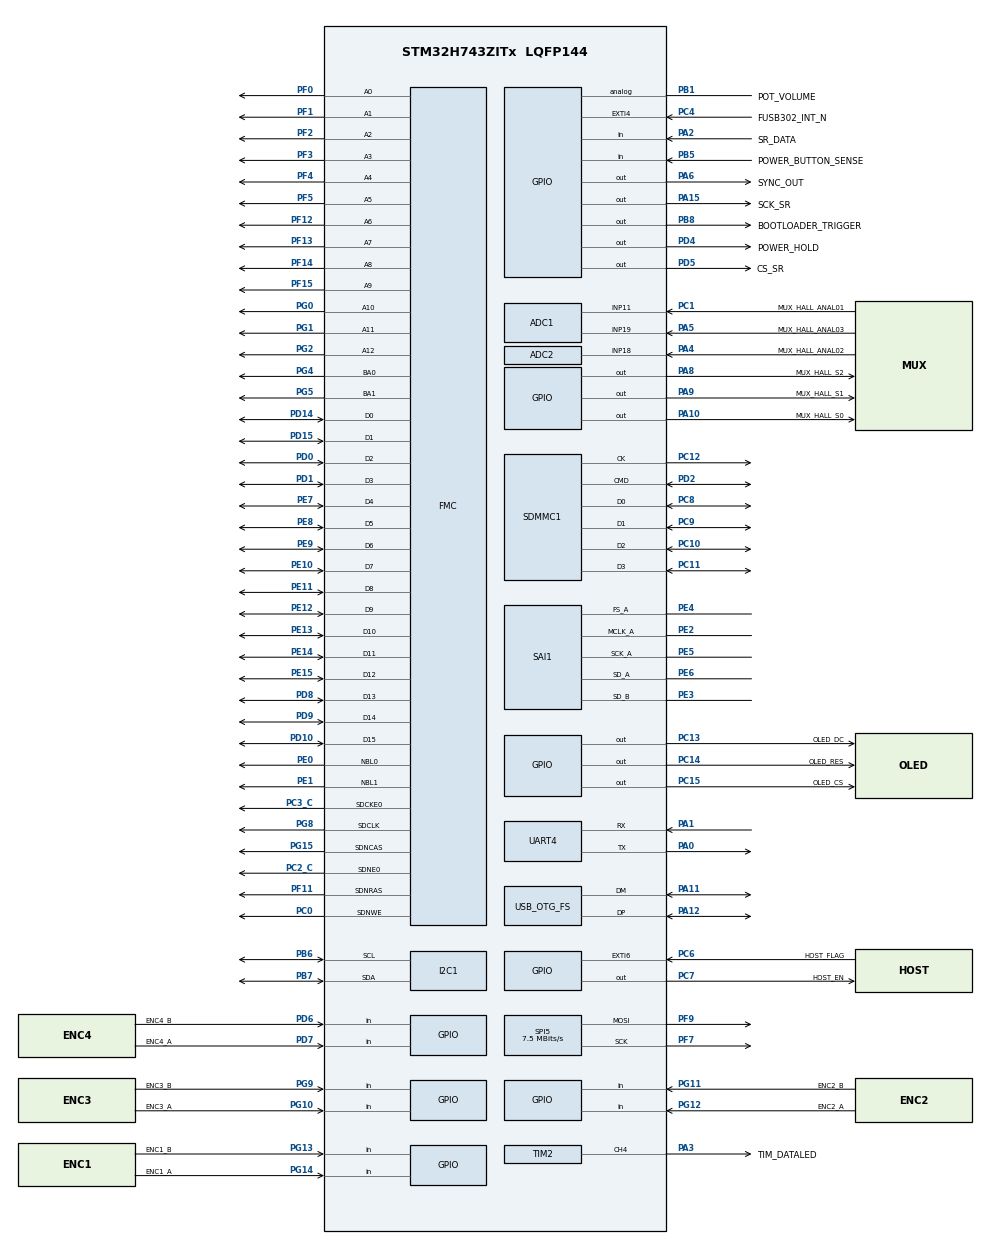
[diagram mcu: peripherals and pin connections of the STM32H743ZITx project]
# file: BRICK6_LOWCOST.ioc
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ADC1.Channel-0\#ChannelRegularConversion=ADC_CHANNEL_11
ADC1.ClockPrescaler=ADC_CLOCK_ASYNC_DIV2
ADC1.ConversionDataManagement=ADC_CONVERSIONDATA_DMA_CIRCULAR
ADC1.ExternalTrigConv=ADC_EXTERNALTRIG_T6_TRGO
ADC1.NbrOfConversionFlag=1
ADC1.OffsetNumber-0\#ChannelRegularConversion=ADC_OFFSET_NONE
ADC1.OffsetSignedSaturation-0\#ChannelRegularConversion=DISABLE
ADC1.Overrun=ADC_OVR_DATA_OVERWRITTEN
ADC1.Rank-0\#ChannelRegularConversion=1
ADC1.SamplingTime-0\#ChannelRegularConversion=ADC_SAMPLETIME_64CYCLES_5
ADC1.master=1
ADC2.Channel-0\#ChannelRegularConversion=ADC_CHANNEL_18
ADC2.ClockPrescaler=ADC_CLOCK_ASYNC_DIV2
ADC2.ConversionDataManagement=ADC_CONVERSIONDATA_DMA_CIRCULAR
ADC2.ExternalTrigConv=ADC_EXTERNALTRIG_T6_TRGO
ADC2.NbrOfConversionFlag=1
ADC2.OffsetNumber-0\#ChannelRegularConversion=ADC_OFFSET_NONE
ADC2.OffsetSignedSaturation-0\#ChannelRegularConversion=DISABLE
ADC2.Overrun=ADC_OVR_DATA_OVERWRITTEN
ADC2.Rank-0\#ChannelRegularConversion=1
ADC2.SamplingTime-0\#ChannelRegularConversion=ADC_SAMPLETIME_64CYCLES_5
CORTEX_M7.CPU_DCache=Enabled
CORTEX_M7.CPU_ICache=Enabled
CORTEX_M7.default_mode_Activation=0
Dma.ADC1.3.Direction=DMA_PERIPH_TO_MEMORY
Dma.ADC1.3.EventEnable=DISABLE
Dma.ADC1.3.FIFOMode=DMA_FIFOMODE_DISABLE
Dma.ADC1.3.Instance=DMA1_Stream1
Dma.ADC1.3.MemDataAlignment=DMA_MDATAALIGN_HALFWORD
Dma.ADC1.3.MemInc=DMA_MINC_ENABLE
Dma.ADC1.3.Mode=DMA_CIRCULAR
Dma.ADC1.3.PeriphDataAlignment=DMA_PDATAALIGN_HALFWORD
Dma.ADC1.3.PeriphInc=DMA_PINC_DISABLE
Dma.ADC1.3.Polarity=HAL_DMAMUX_REQ_GEN_RISING
Dma.ADC1.3.Priority=DMA_PRIORITY_HIGH
Dma.ADC1.3.RequestNumber=1
Dma.ADC1.3.SignalID=NONE
Dma.ADC1.3.SyncEnable=DISABLE
Dma.ADC1.3.SyncPolarity=HAL_DMAMUX_SYNC_NO_EVENT
Dma.ADC1.3.SyncRequestNumber=1
Dma.ADC1.3.SyncSignalID=NONE
Dma.ADC2.4.Direction=DMA_PERIPH_TO_MEMORY
Dma.ADC2.4.EventEnable=DISABLE
Dma.ADC2.4.FIFOMode=DMA_FIFOMODE_DISABLE
Dma.ADC2.4.Instance=DMA1_Stream2
Dma.ADC2.4.MemDataAlignment=DMA_MDATAALIGN_HALFWORD
Dma.ADC2.4.MemInc=DMA_MINC_DISABLE
Dma.ADC2.4.Mode=DMA_CIRCULAR
Dma.ADC2.4.PeriphDataAlignment=DMA_PDATAALIGN_HALFWORD
Dma.ADC2.4.PeriphInc=DMA_PINC_DISABLE
Dma.ADC2.4.Polarity=HAL_DMAMUX_REQ_GEN_RISING
Dma.ADC2.4.Priority=DMA_PRIORITY_HIGH
Dma.ADC2.4.RequestNumber=1
Dma.ADC2.4.SignalID=NONE
Dma.ADC2.4.SyncEnable=DISABLE
Dma.ADC2.4.SyncPolarity=HAL_DMAMUX_SYNC_NO_EVENT
Dma.ADC2.4.SyncRequestNumber=1
Dma.ADC2.4.SyncSignalID=NONE
Dma.Request0=SAI1_A
Dma.Request1=SAI1_B
Dma.Request2=TIM2_CH4
Dma.Request3=ADC1
Dma.Request4=ADC2
Dma.Request5=SPI5_TX
Dma.SAI1_A.0.Direction=DMA_MEMORY_TO_PERIPH
Dma.SAI1_A.0.EventEnable=DISABLE
Dma.SAI1_A.0.FIFOMode=DMA_FIFOMODE_ENABLE
Dma.SAI1_A.0.FIFOThreshold=DMA_FIFO_THRESHOLD_FULL
Dma.SAI1_A.0.Instance=DMA1_Stream3
Dma.SAI1_A.0.MemBurst=DMA_MBURST_SINGLE
Dma.SAI1_A.0.MemDataAlignment=DMA_MDATAALIGN_WORD
Dma.SAI1_A.0.MemInc=DMA_MINC_ENABLE
Dma.SAI1_A.0.Mode=DMA_CIRCULAR
Dma.SAI1_A.0.PeriphBurst=DMA_PBURST_SINGLE
Dma.SAI1_A.0.PeriphDataAlignment=DMA_PDATAALIGN_WORD
Dma.SAI1_A.0.PeriphInc=DMA_PINC_DISABLE
Dma.SAI1_A.0.Polarity=HAL_DMAMUX_REQ_GEN_RISING
Dma.SAI1_A.0.Priority=DMA_PRIORITY_VERY_HIGH
Dma.SAI1_A.0.RequestNumber=1
Dma.SAI1_A.0.SignalID=NONE
Dma.SAI1_A.0.SyncEnable=DISABLE
Dma.SAI1_A.0.SyncPolarity=HAL_DMAMUX_SYNC_NO_EVENT
Dma.SAI1_A.0.SyncRequestNumber=1
Dma.SAI1_A.0.SyncSignalID=NONE
Dma.SAI1_B.1.Direction=DMA_PERIPH_TO_MEMORY
Dma.SAI1_B.1.EventEnable=DISABLE
Dma.SAI1_B.1.FIFOMode=DMA_FIFOMODE_ENABLE
Dma.SAI1_B.1.FIFOThreshold=DMA_FIFO_THRESHOLD_FULL
Dma.SAI1_B.1.Instance=DMA1_Stream4
Dma.SAI1_B.1.MemBurst=DMA_MBURST_SINGLE
Dma.SAI1_B.1.MemDataAlignment=DMA_MDATAALIGN_WORD
Dma.SAI1_B.1.MemInc=DMA_MINC_ENABLE
Dma.SAI1_B.1.Mode=DMA_CIRCULAR
Dma.SAI1_B.1.PeriphBurst=DMA_PBURST_SINGLE
Dma.SAI1_B.1.PeriphDataAlignment=DMA_PDATAALIGN_WORD
Dma.SAI1_B.1.PeriphInc=DMA_PINC_DISABLE
Dma.SAI1_B.1.Polarity=HAL_DMAMUX_REQ_GEN_RISING
Dma.SAI1_B.1.Priority=DMA_PRIORITY_VERY_HIGH
Dma.SAI1_B.1.RequestNumber=1
Dma.SAI1_B.1.SignalID=NONE
Dma.SAI1_B.1.SyncEnable=DISABLE
Dma.SAI1_B.1.SyncPolarity=HAL_DMAMUX_SYNC_NO_EVENT
Dma.SAI1_B.1.SyncRequestNumber=1
Dma.SAI1_B.1.SyncSignalID=NONE
Dma.SPI5_TX.5.Direction=DMA_MEMORY_TO_PERIPH
Dma.SPI5_TX.5.EventEnable=DISABLE
Dma.SPI5_TX.5.FIFOMode=DMA_FIFOMODE_DISABLE
Dma.SPI5_TX.5.Instance=DMA1_Stream5
Dma.SPI5_TX.5.MemDataAlignment=DMA_MDATAALIGN_BYTE
Dma.SPI5_TX.5.MemInc=DMA_MINC_ENABLE
Dma.SPI5_TX.5.Mode=DMA_NORMAL
Dma.SPI5_TX.5.PeriphDataAlignment=DMA_PDATAALIGN_BYTE
Dma.SPI5_TX.5.PeriphInc=DMA_PINC_DISABLE
Dma.SPI5_TX.5.Polarity=HAL_DMAMUX_REQ_GEN_RISING
Dma.SPI5_TX.5.Priority=DMA_PRIORITY_LOW
Dma.SPI5_TX.5.RequestNumber=1
Dma.SPI5_TX.5.SignalID=NONE
Dma.SPI5_TX.5.SyncEnable=DISABLE
Dma.SPI5_TX.5.SyncPolarity=HAL_DMAMUX_SYNC_NO_EVENT
Dma.SPI5_TX.5.SyncRequestNumber=1
Dma.SPI5_TX.5.SyncSignalID=NONE
Dma.TIM2_CH4.2.Direction=DMA_MEMORY_TO_PERIPH
Dma.TIM2_CH4.2.EventEnable=DISABLE
Dma.TIM2_CH4.2.FIFOMode=DMA_FIFOMODE_DISABLE
Dma.TIM2_CH4.2.Instance=DMA1_Stream0
Dma.TIM2_CH4.2.MemDataAlignment=DMA_MDATAALIGN_WORD
Dma.TIM2_CH4.2.MemInc=DMA_MINC_ENABLE
Dma.TIM2_CH4.2.Mode=DMA_NORMAL
Dma.TIM2_CH4.2.PeriphDataAlignment=DMA_PDATAALIGN_WORD
Dma.TIM2_CH4.2.PeriphInc=DMA_PINC_DISABLE
Dma.TIM2_CH4.2.Polarity=HAL_DMAMUX_REQ_GEN_RISING
Dma.TIM2_CH4.2.Priority=DMA_PRIORITY_HIGH
Dma.TIM2_CH4.2.RequestNumber=1
Dma.TIM2_CH4.2.SignalID=NONE
Dma.TIM2_CH4.2.SyncEnable=DISABLE
Dma.TIM2_CH4.2.SyncPolarity=HAL_DMAMUX_SYNC_NO_EVENT
Dma.TIM2_CH4.2.SyncRequestNumber=1
Dma.TIM2_CH4.2.SyncSignalID=NONE
FMC.CASLatency1=FMC_SDRAM_CAS_LATENCY_3
FMC.ColumnBitsNumber1=FMC_SDRAM_COLUMN_BITS_NUM_9
FMC.ExitSelfRefreshDelay1=7
FMC.LoadToActiveDelay1=2
FMC.RCDDelay1=2
FMC.RPDelay1=2
FMC.ReadBurst1=FMC_SDRAM_RBURST_ENABLE
FMC.ReadPipeDelay1=FMC_SDRAM_RPIPE_DELAY_1
FMC.RowCycleDelay1=7
FMC.SDClockPeriod1=FMC_SDRAM_CLOCK_PERIOD_2
FMC.SelfRefreshTime1=4
FMC.WriteRecoveryTime1=3
I2C1.Timing=0x307075B1
Mcu.Family=STM32H7
Mcu.Name=STM32H743ZITx
Mcu.Package=LQFP144
NVIC.DMA1_Stream0_IRQn=true\:5\:0\:true\:false\:true\:false\:true\:true
NVIC.DMA1_Stream1_IRQn=true\:5\:0\:true\:false\:true\:false\:true\:true
NVIC.DMA1_Stream2_IRQn=true\:5\:0\:true\:false\:true\:false\:true\:true
NVIC.DMA1_Stream3_IRQn=true\:1\:0\:true\:false\:true\:false\:true\:true
NVIC.DMA1_Stream4_IRQn=true\:1\:0\:true\:false\:true\:false\:true\:true
NVIC.DMA1_Stream5_IRQn=true\:5\:0\:true\:false\:true\:false\:true\:true
NVIC.EXTI4_IRQn=true\:5\:0\:true\:false\:true\:true\:true\:true
NVIC.EXTI9_5_IRQn=true\:5\:0\:true\:false\:true\:true\:true\:true
NVIC.OTG_FS_IRQn=true\:6\:0\:true\:false\:true\:true\:true\:true
NVIC.PriorityGroup=NVIC_PRIORITYGROUP_4
NVIC.SAI1_IRQn=true\:1\:0\:true\:false\:true\:true\:true\:true
NVIC.SDMMC1_IRQn=true\:1\:0\:true\:false\:true\:true\:true\:true
NVIC.SPI5_IRQn=true\:5\:0\:true\:false\:true\:true\:true\:true
NVIC.TIM5_IRQn=true\:5\:0\:true\:false\:true\:true\:true\:true
NVIC.TIM7_IRQn=true\:6\:0\:true\:false\:true\:true\:true\:true
NVIC.TIM8_BRK_TIM12_IRQn=true\:5\:0\:true\:false\:true\:true\:true\:true
PA0.Mode=Asynchronous
PA0.Signal=UART4_TX
PA1.Mode=Asynchronous
PA1.Signal=UART4_RX
PA10.GPIO_Label=MUX_HALL_S0
PA10.Signal=GPIO_Output
PA11.Mode=Device_Only
PA11.Signal=USB_OTG_FS_DM
PA12.Mode=Device_Only
PA12.Signal=USB_OTG_FS_DP
PA15\ (JTDI).GPIO_Label=SCK_SR
PA15\ (JTDI).Signal=GPIO_Output
PA2.GPIO_Label=SR_DATA
PA2.GPIO_PuPd=GPIO_PULLUP
PA2.Signal=GPIO_Input
PA3.GPIO_Label=TIM_DATALED
PA3.GPIO_Speed=GPIO_SPEED_FREQ_VERY_HIGH
PA3.Signal=S_TIM2_CH4
PA4.GPIO_Label=MUX_HALL_ANAL02
PA4.Signal=ADCx_INP18
PA5.GPIO_Label=MUX_HALL_ANAL03
PA5.Signal=ADCx_INP19
PA6.GPIO_Label=SYNC_OUT
PA6.Signal=GPIO_Output
PA8.GPIO_Label=MUX_HALL_S2
PA8.Signal=GPIO_Output
PA9.GPIO_Label=MUX_HALL_S1
PA9.Signal=GPIO_Output
PB1.GPIO_Label=POT_VOLUME
PB1.Signal=GPIO_Analog
PB5.GPIO_Label=POWER_BUTTON_SENSE
PB5.GPIO_PuPd=GPIO_NOPULL
PB5.Signal=GPIO_Input
PB6.Mode=I2C
PB6.Signal=I2C1_SCL
PB7.Mode=I2C
PB7.Signal=I2C1_SDA
PB8.GPIO_Label=BOOTLOADER_TRIGGER
PB8.GPIO_Speed=GPIO_SPEED_FREQ_LOW
PB8.PinState=GPIO_PIN_RESET
PB8.Signal=GPIO_Output
PC0.Signal=FMC_SDNWE
PC1.GPIO_Label=MUX_HALL_ANAL01
PC1.Signal=ADCx_INP11
PC10.GPIO_PuPd=GPIO_PULLUP
PC10.Mode=SD_4_bits_Wide_bus
PC10.Signal=SDMMC1_D2
PC11.GPIO_PuPd=GPIO_PULLUP
PC11.Mode=SD_4_bits_Wide_bus
PC11.Signal=SDMMC1_D3
PC12.GPIO_PuPd=GPIO_NOPULL
PC12.Mode=SD_4_bits_Wide_bus
PC12.Signal=SDMMC1_CK
PC13.GPIO_Label=OLED_DC
PC13.GPIO_Speed=GPIO_SPEED_FREQ_LOW
PC13.PinState=GPIO_PIN_SET
PC13.Signal=GPIO_Output
PC14-OSC32_IN\ (OSC32_IN).GPIO_Label=OLED_RES
PC14-OSC32_IN\ (OSC32_IN).GPIO_Speed=GPIO_SPEED_FREQ_LOW
PC14-OSC32_IN\ (OSC32_IN).PinState=GPIO_PIN_RESET
PC14-OSC32_IN\ (OSC32_IN).Signal=GPIO_Output
PC15-OSC32_OUT\ (OSC32_OUT).GPIO_Label=OLED_CS
PC15-OSC32_OUT\ (OSC32_OUT).GPIO_Speed=GPIO_SPEED_FREQ_LOW
PC15-OSC32_OUT\ (OSC32_OUT).PinState=GPIO_PIN_SET
PC15-OSC32_OUT\ (OSC32_OUT).Signal=GPIO_Output
PC2_C.Mode=SdramChipSelect1_1
PC2_C.Signal=FMC_SDNE0
PC3_C.Mode=SdramChipSelect1_1
PC3_C.Signal=FMC_SDCKE0
PC4.GPIO_Label=FUSB302_INT_N
PC4.GPIO_ModeDefaultEXTI=GPIO_MODE_IT_FALLING
PC4.GPIO_PuPd=GPIO_PULLUP
PC4.Signal=GPXTI4
PC6.GPIO_Label=HOST_FLAG
PC6.GPIO_PuPd=GPIO_PULLUP
PC6.GPIO_ModeDefaultEXTI=GPIO_MODE_IT_RISING_FALLING
PC6.Signal=GPXTI6
PC7.GPIO_Label=HOST_EN
PC7.GPIO_Speed=GPIO_SPEED_FREQ_LOW
PC7.PinState=GPIO_PIN_SET
PC7.Signal=GPIO_Output
PC8.GPIO_PuPd=GPIO_PULLUP
PC8.Mode=SD_4_bits_Wide_bus
PC8.Signal=SDMMC1_D0
PC9.GPIO_PuPd=GPIO_PULLUP
PC9.Mode=SD_4_bits_Wide_bus
PC9.Signal=SDMMC1_D1
PD0.Signal=FMC_D2_DA2
PD1.Signal=FMC_D3_DA3
PD10.Signal=FMC_D15_DA15
PD14.Signal=FMC_D0_DA0
PD15.Signal=FMC_D1_DA1
PD2.GPIO_PuPd=GPIO_PULLUP
PD2.Mode=SD_4_bits_Wide_bus
PD2.Signal=SDMMC1_CMD
PD4.GPIO_Label=POWER_HOLD
PD4.GPIO_Speed=GPIO_SPEED_FREQ_LOW
PD4.PinState=GPIO_PIN_RESET
PD4.Signal=GPIO_Output
PD5.GPIO_Label=CS_SR
PD5.GPIO_Speed=GPIO_SPEED_FREQ_LOW
PD5.PinState=GPIO_PIN_SET
PD5.Signal=GPIO_Output
PD6.GPIO_Label=ENC4_B
PD6.GPIO_PuPd=GPIO_PULLUP
PD6.Signal=GPIO_Input
PD7.GPIO_Label=ENC4_A
PD7.GPIO_PuPd=GPIO_PULLUP
PD7.Signal=GPIO_Input
PD8.Signal=FMC_D13_DA13
PD9.Signal=FMC_D14_DA14
PE0.Signal=FMC_NBL0
PE1.Signal=FMC_NBL1
PE10.Signal=FMC_D7_DA7
PE11.Signal=FMC_D8_DA8
PE12.Signal=FMC_D9_DA9
PE13.Signal=FMC_D10_DA10
PE14.Signal=FMC_D11_DA11
PE15.Signal=FMC_D12_DA12
PE2.Mode=SAI_A_MasterWithClock
PE2.Signal=SAI1_MCLK_A
PE3.Mode=SAI_B_SyncSlave
PE3.Signal=SAI1_SD_B
PE4.Mode=SAI_A_MasterWithClock
PE4.Signal=SAI1_FS_A
PE5.Mode=SAI_A_MasterWithClock
PE5.Signal=SAI1_SCK_A
PE6.Mode=SAI_A_MasterWithClock
PE6.Signal=SAI1_SD_A
PE7.Signal=FMC_D4_DA4
PE8.Signal=FMC_D5_DA5
PE9.Signal=FMC_D6_DA6
PF0.Signal=FMC_A0
PF1.Signal=FMC_A1
PF11.Signal=FMC_SDNRAS
PF12.Signal=FMC_A6
PF13.Signal=FMC_A7
PF14.Signal=FMC_A8
PF15.Signal=FMC_A9
PF2.Signal=FMC_A2
PF3.Signal=FMC_A3
PF4.Signal=FMC_A4
PF5.Signal=FMC_A5
PF7.GPIO_Speed=GPIO_SPEED_FREQ_VERY_HIGH
PF7.Mode=TX_Only_Simplex_Unidirect_Master
PF7.Signal=SPI5_SCK
PF9.GPIO_Speed=GPIO_SPEED_FREQ_VERY_HIGH
PF9.Mode=TX_Only_Simplex_Unidirect_Master
PF9.Signal=SPI5_MOSI
PG0.Signal=FMC_A10
PG1.Signal=FMC_A11
PG10.GPIO_Label=ENC3_A
PG10.GPIO_PuPd=GPIO_PULLUP
PG10.Signal=GPIO_Input
PG11.GPIO_Label=ENC2_B
PG11.GPIO_PuPd=GPIO_PULLUP
PG11.Signal=GPIO_Input
PG12.GPIO_Label=ENC2_A
PG12.GPIO_PuPd=GPIO_PULLUP
PG12.Signal=GPIO_Input
PG13.GPIO_Label=ENC1_B
PG13.GPIO_PuPd=GPIO_PULLUP
PG13.Signal=GPIO_Input
PG14.GPIO_Label=ENC1_A
PG14.GPIO_PuPd=GPIO_PULLUP
PG14.Signal=GPIO_Input
PG15.Signal=FMC_SDNCAS
PG2.Signal=FMC_A12
PG4.Signal=FMC_A14_BA0
PG5.Signal=FMC_A15_BA1
PG8.Signal=FMC_SDCLK
PG9.GPIO_Label=ENC3_B
PG9.GPIO_PuPd=GPIO_PULLUP
PG9.Signal=GPIO_Input
PH0-OSC_IN\ (PH0).Mode=HSE-External-Oscillator
PH0-OSC_IN\ (PH0).Signal=RCC_OSC_IN
PH1-OSC_OUT\ (PH1).Mode=HSE-External-Oscillator
PH1-OSC_OUT\ (PH1).Signal=RCC_OSC_OUT
ProjectManager.HeapSize=0x200
ProjectManager.StackSize=0x400
ProjectManager.TargetToolchain=CMake
RCC.ADCFreq_Value=30000000
RCC.APB1Freq_Value=120000000
RCC.APB2Freq_Value=120000000
RCC.APB3Freq_Value=120000000
RCC.APB4Freq_Value=120000000
RCC.CortexFreq_Value=480000000
RCC.D1PPRE=RCC_APB3_DIV2
RCC.D2PPRE1=RCC_APB1_DIV2
RCC.D2PPRE2=RCC_APB2_DIV2
RCC.D3PPRE=RCC_APB4_DIV2
RCC.DIVM1=3
RCC.DIVM2=3
RCC.DIVM3=5
RCC.DIVN1=240
RCC.DIVN2=150
RCC.DIVN3=256
RCC.DIVP2=20
RCC.DIVP3=25
RCC.DIVQ1=20
RCC.DIVQ2=1
RCC.DIVR2=3
RCC.FMCCLockSelection=RCC_FMCCLKSOURCE_D1HCLK
RCC.HCLKFreq_Value=240000000
RCC.HPRE=RCC_HCLK_DIV2
RCC.HSE_VALUE=12000000
RCC.PLL1_VCI_Range-AdvancedSettings=RCC_PLL1VCIRANGE_1
RCC.PLL2FRACN=0
RCC.PLL3FRACN=0
RCC.PLL3_VCI_Range-AdvancedSettings=RCC_PLL3VCIRANGE_1
RCC.PLL3_VCO_SEL-AdvancedSettings=RCC_PLL3VCOWIDE
RCC.PLLFRACN=0
RCC.PLLSourceVirtual=RCC_PLLSOURCE_HSE
RCC.SAI1CLockSelection=RCC_SAI1CLKSOURCE_PLL3
RCC.SDMMC1CLockSelection=RCC_SDMMCCLKSOURCE_PLL2
RCC.SYSCLKFreq_VALUE=480000000
RCC.SYSCLKSource=RCC_SYSCLKSOURCE_PLLCLK
RCC.USBCLockSelection=RCC_USBCLKSOURCE_HSI48
RCC.USBFreq_Value=48000000
SAI1.ActiveFrameLength-SAI_A_MasterWithClock=32
SAI1.ActiveFrameLength-SAI_B_SyncSlave=32
SAI1.AudioFrequency-SAI_A_MasterWithClock=SAI_AUDIO_FREQUENCY_48K
SAI1.ClockStrobing-SAI_A_MasterWithClock=SAI_CLOCKSTROBING_FALLINGEDGE
SAI1.ClockStrobing-SAI_B_SyncSlave=SAI_CLOCKSTROBING_FALLINGEDGE
SAI1.DataSize-SAI_A_MasterWithClock=SAI_DATASIZE_24
SAI1.DataSize-SAI_B_SyncSlave=SAI_DATASIZE_24
SAI1.ErrorAudioFreq-SAI_A_MasterWithClock=0.0 %
SAI1.FIFOThreshold-SAI_A_MasterWithClock=SAI_FIFOTHRESHOLD_FULL
SAI1.FIFOThreshold-SAI_B_SyncSlave=SAI_FIFOTHRESHOLD_FULL
SAI1.FSOffset-SAI_A_MasterWithClock=SAI_FS_BEFOREFIRSTBIT
SAI1.FSOffset-SAI_B_SyncSlave=SAI_FS_BEFOREFIRSTBIT
SAI1.FSPolarity-SAI_A_MasterWithClock=SAI_FS_ACTIVE_LOW
SAI1.FSPolarity-SAI_B_SyncSlave=SAI_FS_ACTIVE_LOW
SAI1.FrameLength-SAI_A_MasterWithClock=64
SAI1.FrameLength-SAI_B_SyncSlave=64
SAI1.Instance-SAI_A_MasterWithClock=SAI$Index_Block_A
SAI1.Instance-SAI_B_SyncSlave=SAI$Index_Block_B
SAI1.MClockEnable-SAI_A_MasterWithClock=SAI_MASTERCLOCK_ENABLE
SAI1.OutputDrive-SAI_A_MasterWithClock=SAI_OUTPUTDRIVE_DISABLE
SAI1.OutputDrive-SAI_B_SyncSlave=SAI_OUTPUTDRIVE_DISABLE
SAI1.RealAudioFreq-SAI_A_MasterWithClock=48.0 KHz
SAI1.SlotActive-SAI_A_MasterWithClock=0x00000003
SAI1.SlotActive-SAI_B_SyncSlave=0x00000003
SAI1.SlotNumber-SAI_A_MasterWithClock=2
SAI1.SlotNumber-SAI_B_SyncSlave=2
SAI1.SlotSize-SAI_A_MasterWithClock=SAI_SLOTSIZE_32B
SAI1.SlotSize-SAI_B_SyncSlave=SAI_SLOTSIZE_32B
SAI1.SynchroExt=SAI_SYNCEXT_OUTBLOCKA_ENABLE
SAI1.VirtualMode-SAI_A_MasterWithClock=VM_MASTER
SAI1.VirtualMode-SAI_B_SyncSlave=VM_SLAVE
SAI1.VirtualSlotActive-SAI_A_MasterWithClock=SAI_SLOT_USERSETTING
SAI1.VirtualSlotActive-SAI_B_SyncSlave=SAI_SLOT_USERSETTING
SAI1.VirtualSlotActive0-SAI_A_MasterWithClock=true
SAI1.VirtualSlotActive0-SAI_B_SyncSlave=true
SAI1.VirtualSlotActive1-SAI_A_MasterWithClock=true
SAI1.VirtualSlotActive1-SAI_B_SyncSlave=true
SDMMC1.ClockDiv=4
SDMMC1.ClockEdge=SDMMC_CLOCK_EDGE_RISING
SDMMC1.HardwareFlowControl=SDMMC_HARDWARE_FLOW_CONTROL_DISABLE
SH.ADCx_INP11.0=ADC1_INP11,IN11-Single-Ended
SH.ADCx_INP18.0=ADC2_INP18,IN18-Single-Ended
SH.ADCx_INP19.0=ADC1_INP19,IN19-Single-Ended
SH.FMC_A0.0=FMC_A0,13b-sda1
SH.FMC_A1.0=FMC_A1,13b-sda1
SH.FMC_A10.0=FMC_A10,13b-sda1
SH.FMC_A11.0=FMC_A11,13b-sda1
SH.FMC_A12.0=FMC_A12,13b-sda1
SH.FMC_A14_BA0.0=FMC_BA0,FourSdramBanks1
SH.FMC_A15_BA1.0=FMC_BA1,FourSdramBanks1
SH.FMC_A2.0=FMC_A2,13b-sda1
SH.FMC_A3.0=FMC_A3,13b-sda1
SH.FMC_A4.0=FMC_A4,13b-sda1
SH.FMC_A5.0=FMC_A5,13b-sda1
SH.FMC_A6.0=FMC_A6,13b-sda1
SH.FMC_A7.0=FMC_A7,13b-sda1
SH.FMC_A8.0=FMC_A8,13b-sda1
SH.FMC_A9.0=FMC_A9,13b-sda1
SH.FMC_D0_DA0.0=FMC_D0,sd-16b-d1
SH.FMC_D10_DA10.0=FMC_D10,sd-16b-d1
SH.FMC_D11_DA11.0=FMC_D11,sd-16b-d1
SH.FMC_D12_DA12.0=FMC_D12,sd-16b-d1
SH.FMC_D13_DA13.0=FMC_D13,sd-16b-d1
SH.FMC_D14_DA14.0=FMC_D14,sd-16b-d1
SH.FMC_D15_DA15.0=FMC_D15,sd-16b-d1
SH.FMC_D1_DA1.0=FMC_D1,sd-16b-d1
SH.FMC_D2_DA2.0=FMC_D2,sd-16b-d1
SH.FMC_D3_DA3.0=FMC_D3,sd-16b-d1
SH.FMC_D4_DA4.0=FMC_D4,sd-16b-d1
SH.FMC_D5_DA5.0=FMC_D5,sd-16b-d1
SH.FMC_D6_DA6.0=FMC_D6,sd-16b-d1
SH.FMC_D7_DA7.0=FMC_D7,sd-16b-d1
SH.FMC_D8_DA8.0=FMC_D8,sd-16b-d1
SH.FMC_D9_DA9.0=FMC_D9,sd-16b-d1
SH.FMC_NBL0.0=FMC_NBL0,Sd2ByteEnable1
SH.FMC_NBL1.0=FMC_NBL1,Sd2ByteEnable1
SH.FMC_SDCLK.0=FMC_SDCLK,13b-sda1
SH.FMC_SDNCAS.0=FMC_SDNCAS,13b-sda1
SH.FMC_SDNRAS.0=FMC_SDNRAS,13b-sda1
SH.FMC_SDNWE.0=FMC_SDNWE,13b-sda1
SH.S_TIM2_CH4.0=TIM2_CH4,PWM Generation4 CH4
SPI5.BaudRatePrescaler=SPI_BAUDRATEPRESCALER_16
SPI5.CalculateBaudRate=7.5 MBits/s
SPI5.DataSize=SPI_DATASIZE_8BIT
SPI5.Direction=SPI_DIRECTION_2LINES_TXONLY
SPI5.Mode=SPI_MODE_MASTER
SPI5.NSSPMode=SPI_NSS_PULSE_DISABLE
SPI5.VirtualType=VM_MASTER
TIM12.Period=999
TIM12.Prescaler=159
TIM2.Channel-PWM\ Generation4\ CH4=TIM_CHANNEL_4
TIM2.Period=299
TIM5.Channel-Output\ Compare1\ No\ Output=TIM_CHANNEL_1
TIM5.Prescaler=239
TIM5.Pulse-Output\ Compare1\ No\ Output=1000
TIM6.Period=49
TIM6.Prescaler=239
TIM6.TIM_MasterOutputTrigger=TIM_TRGO_UPDATE
TIM7.Period=199
TIM7.Prescaler=191
UART4.VirtualMode-Asynchronous=VM_ASYNC
USB_OTG_FS.VirtualMode=Device_Only
VP_MEMORYMAP_VS_MEMORYMAP.Mode=CurAppReg
VP_TIM12_VS_ClockSourceINT.Mode=Internal
VP_TIM2_VS_ClockSourceINT.Mode=Internal
VP_TIM5_VS_ClockSourceINT.Mode=Internal
VP_TIM5_VS_no_output1.Mode=Output Compare1 No Output
VP_TIM6_VS_ClockSourceINT.Mode=Enable_Timer
VP_TIM7_VS_ClockSourceINT.Mode=Enable_Timer
board=custom

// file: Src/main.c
/* USER CODE BEGIN Header */
/**
  ******************************************************************************
  * @file           : main.c
  * @brief          : Main program body
  ******************************************************************************
  * @attention
  *
  * Copyright (c) 2026 STMicroelectronics.
  * All rights reserved.
  *
  * This software is licensed under terms that can be found in the LICENSE file
  * in the root directory of this software component.
  * If no LICENSE file comes with this software, it is provided AS-IS.
  *
  ******************************************************************************
  */
/* USER CODE END Header */
#include "main.h"
#include "adc.h"
#include "dma.h"
#include "i2c.h"
#include "sai.h"
#include "sdmmc.h"
#include "spi.h"
#include "tim.h"
#include "usart.h"
#include "gpio.h"
#include "fmc.h"

/* USER CODE BEGIN Includes */
#include "Board/board_usb.h"
#include "sdram.h"
#include "App/engine_tasklet.h"
#include "ui_tasklet.h"
#include "App/brick6_app_init.h"
#include "audio.h"
#include "audio_float.h"
#include "fatfs.h"
#include "led_rgb.h"
#include "led_ids.h"
#include "display_flush_service.h"
#include "ui_renderer_oled.h"
#include "Board/board_power.h"
#include "buttons.h"
#include "App/power_shutdown.h"
/* USER CODE END Includes */

void SystemClock_Config(void);
void PeriphCommonClock_Config(void);
/* USER CODE BEGIN PFP */
static void MPU_Config(void);
/* USER CODE END PFP */

/* USER CODE BEGIN 0 */
extern uint32_t __ram_d2_dma_start__;
extern uint32_t __ram_d2_dma_end__;
extern uint32_t __ram_d2_dma_audio_start__;
extern uint32_t __ram_d2_dma_audio_end__;
extern uint32_t __ram_d2_dma_cacheable_start__;
extern uint32_t __ram_d2_dma_cacheable_end__;
extern uint32_t __stack_guard_start__;
extern uint32_t __stack_limit__;
extern uint32_t _estack;

#define RAM_D2_DMA_MPU_BASE               (0x30000000UL)
#define RAM_D2_DMA_MPU_COVERED_BYTES      (12UL * 1024UL)
#define RAM_D2_DMA_MPU_SUBREGION_DISABLE  (0xF8U)
#define RAM_D2_DMA_CACHEABLE_BASE         (0x30003000UL)
#define RAM_D2_DMA_CACHEABLE_END          (0x30020000UL)
#define BACKUP_SRAM_MPU_BASE               (0x38800000UL)
#define RAM_D3_IRQ_SHARED_MPU_BASE                 (0x38008000UL)
#define SDRAM_MPU_BASE                     (0xC0000000UL)
#define MSP_GUARD_BYTES                    (4UL * 1024UL)
#define MSP_PROVISIONAL_STACK_BYTES        (24UL * 1024UL)
#define MSP_STACK_FILL_WORD                (0xA55AA55AUL)
#define MSP_MONITOR_WORDS_PER_SERVICE      (64UL)
#define UI_TASKLET_ENGINE_DIVIDER         (4UL)
#define UI_TASKLET_CATCHUP_BUDGET         (8UL)
#define LOWCOST_BOOTLOADER_SHIFT_STEP16_ENABLE     1U
#define LOWCOST_BOOTLOADER_HOLD_MS                 2000UL

__attribute__((section(".ram_d3_ctrl")))
volatile uint32_t g_msp_stack_high_water_bytes;
__attribute__((section(".ram_d3_ctrl")))
volatile uint32_t g_msp_stack_capacity_bytes;
__attribute__((section(".ram_d3_ctrl")))
static uintptr_t g_msp_stack_scan_address;
__attribute__((section(".ram_d3_ctrl")))
static uintptr_t g_msp_stack_lowest_touched;

static void msp_stack_monitor_init(void)
{
  const uintptr_t stack_limit = (uintptr_t)&__stack_limit__;
  const uintptr_t stack_end = (uintptr_t)&_estack;
  g_msp_stack_capacity_bytes = (uint32_t)(stack_end - stack_limit);
  g_msp_stack_high_water_bytes = 0U;
  g_msp_stack_scan_address = stack_limit;
  g_msp_stack_lowest_touched = stack_end;
}

static void msp_stack_monitor_service(void)
{
  const uintptr_t stack_limit = (uintptr_t)&__stack_limit__;
  const uintptr_t stack_end = (uintptr_t)&_estack;
  uintptr_t scan = g_msp_stack_scan_address;
  uintptr_t lowest = g_msp_stack_lowest_touched;
  for (uint32_t word = 0U; word < MSP_MONITOR_WORDS_PER_SERVICE; ++word)
  {
    if (*(const volatile uint32_t *)scan != MSP_STACK_FILL_WORD && scan < lowest)
      lowest = scan;
    scan += sizeof(uint32_t);
    if (scan >= stack_end) scan = stack_limit;
  }
  g_msp_stack_scan_address = scan;
  g_msp_stack_lowest_touched = lowest;
  g_msp_stack_high_water_bytes = (uint32_t)(stack_end - lowest);
}

static void MPU_Config(void)
{
  MPU_Region_InitTypeDef MPU_InitStruct = {0};

  HAL_MPU_Disable();

  MPU_InitStruct.Enable = MPU_REGION_ENABLE;
  MPU_InitStruct.Number = MPU_REGION_NUMBER1;
  MPU_InitStruct.BaseAddress = RAM_D2_DMA_MPU_BASE;
  MPU_InitStruct.Size = MPU_REGION_SIZE_32KB;
  MPU_InitStruct.SubRegionDisable = RAM_D2_DMA_MPU_SUBREGION_DISABLE;
  MPU_InitStruct.TypeExtField = MPU_TEX_LEVEL1;
  MPU_InitStruct.AccessPermission = MPU_REGION_FULL_ACCESS;
  MPU_InitStruct.DisableExec = MPU_INSTRUCTION_ACCESS_DISABLE;
  MPU_InitStruct.IsShareable = MPU_ACCESS_SHAREABLE;
  MPU_InitStruct.IsCacheable = MPU_ACCESS_NOT_CACHEABLE;
  MPU_InitStruct.IsBufferable = MPU_ACCESS_NOT_BUFFERABLE;

  HAL_MPU_ConfigRegion(&MPU_InitStruct);

  /* Crash-library GDB view/command mailbox: debugger-coherent and retained.
     Region 2 was intentionally free; do not let D-cache hide CPU writes from
     GDB or a GDB CLEAR write from the firmware. */
  MPU_InitStruct.Number = MPU_REGION_NUMBER2;
  MPU_InitStruct.BaseAddress = BACKUP_SRAM_MPU_BASE;
  MPU_InitStruct.Size = MPU_REGION_SIZE_4KB;
  MPU_InitStruct.SubRegionDisable = 0x00U;
  MPU_InitStruct.TypeExtField = MPU_TEX_LEVEL1;
  MPU_InitStruct.AccessPermission = MPU_REGION_FULL_ACCESS;
  MPU_InitStruct.DisableExec = MPU_INSTRUCTION_ACCESS_DISABLE;
  MPU_InitStruct.IsShareable = MPU_ACCESS_SHAREABLE;
  MPU_InitStruct.IsCacheable = MPU_ACCESS_NOT_CACHEABLE;
  MPU_InitStruct.IsBufferable = MPU_ACCESS_NOT_BUFFERABLE;
  HAL_MPU_ConfigRegion(&MPU_InitStruct);

  MPU_InitStruct.Number = MPU_REGION_NUMBER3;
  MPU_InitStruct.BaseAddress = SDRAM_MPU_BASE;
  MPU_InitStruct.Size = MPU_REGION_SIZE_32MB;
  MPU_InitStruct.SubRegionDisable = 0x00U;
  MPU_InitStruct.TypeExtField = MPU_TEX_LEVEL0;
  MPU_InitStruct.AccessPermission = MPU_REGION_FULL_ACCESS;
  MPU_InitStruct.DisableExec = MPU_INSTRUCTION_ACCESS_DISABLE;
  MPU_InitStruct.IsShareable = MPU_ACCESS_NOT_SHAREABLE;
  MPU_InitStruct.IsCacheable = MPU_ACCESS_CACHEABLE;
  MPU_InitStruct.IsBufferable = MPU_ACCESS_BUFFERABLE;
  HAL_MPU_ConfigRegion(&MPU_InitStruct);

  /* Region 7 overrides the privileged default map for the page immediately
     below MSP.  Any downward stack access faults before reaching reclaimed
     D1, the bounded heap, or static storage. */
  MPU_InitStruct.Number = MPU_REGION_NUMBER7;
  MPU_InitStruct.BaseAddress = (uint32_t)&__stack_guard_start__;
  MPU_InitStruct.Size = MPU_REGION_SIZE_4KB;
  MPU_InitStruct.SubRegionDisable = 0x00U;
  MPU_InitStruct.TypeExtField = MPU_TEX_LEVEL0;
  MPU_InitStruct.AccessPermission = MPU_REGION_NO_ACCESS;
  MPU_InitStruct.DisableExec = MPU_INSTRUCTION_ACCESS_DISABLE;
  MPU_InitStruct.IsShareable = MPU_ACCESS_SHAREABLE;
  MPU_InitStruct.IsCacheable = MPU_ACCESS_NOT_CACHEABLE;
  MPU_InitStruct.IsBufferable = MPU_ACCESS_NOT_BUFFERABLE;
  HAL_MPU_ConfigRegion(&MPU_InitStruct);

  MPU_InitStruct.Number = MPU_REGION_NUMBER5;
  MPU_InitStruct.BaseAddress = RAM_D3_IRQ_SHARED_MPU_BASE;
  MPU_InitStruct.Size = MPU_REGION_SIZE_32KB;
  MPU_InitStruct.SubRegionDisable = 0x00U;
  MPU_InitStruct.TypeExtField = MPU_TEX_LEVEL1;
  MPU_InitStruct.AccessPermission = MPU_REGION_FULL_ACCESS;
  MPU_InitStruct.DisableExec = MPU_INSTRUCTION_ACCESS_DISABLE;
  MPU_InitStruct.IsShareable = MPU_ACCESS_SHAREABLE;
  MPU_InitStruct.IsCacheable = MPU_ACCESS_NOT_CACHEABLE;
  MPU_InitStruct.IsBufferable = MPU_ACCESS_NOT_BUFFERABLE;
  HAL_MPU_ConfigRegion(&MPU_InitStruct);

  SCB->SHCSR |= SCB_SHCSR_MEMFAULTENA_Msk;
  HAL_MPU_Enable(MPU_PRIVILEGED_DEFAULT);
  __DSB();
  __ISB();
}

static void lowcost_bootloader_shift_step16_service(void)
{
#if LOWCOST_BOOTLOADER_SHIFT_STEP16_ENABLE
  static uint8_t combo_was_down = 0U;
  static uint8_t fired = 0U;
  static uint32_t hold_start_ms = 0U;

  const uint8_t combo_down =
      ((button_down(BTN_SHIFT) != 0U) && (button_down(BTN_STEP_16) != 0U)) ? 1U : 0U;
  const uint32_t now_ms = HAL_GetTick();

  if (combo_down == 0U)
  {
    combo_was_down = 0U;
    fired = 0U;
    hold_start_ms = 0U;
    return;
  }

  if (combo_was_down == 0U)
  {
    combo_was_down = 1U;
    hold_start_ms = now_ms;
    return;
  }

  if ((fired == 0U) && ((uint32_t)(now_ms - hold_start_ms) >= LOWCOST_BOOTLOADER_HOLD_MS))
  {
    fired = 1U;
    board_power_enter_rom_dfu();
  }
#endif
}

/* USER CODE END 0 */

int main(void)
{

  /* USER CODE BEGIN 1 */
  const uintptr_t dma_start = (uintptr_t)&__ram_d2_dma_start__;
  const uintptr_t dma_end = (uintptr_t)&__ram_d2_dma_end__;

  if ((dma_start < RAM_D2_DMA_MPU_BASE) ||
      (dma_end > (RAM_D2_DMA_MPU_BASE + RAM_D2_DMA_MPU_COVERED_BYTES)))
  {
    Error_Handler();
  }

  const uintptr_t dma_audio_start = (uintptr_t)&__ram_d2_dma_audio_start__;
  const uintptr_t dma_audio_end = (uintptr_t)&__ram_d2_dma_audio_end__;
  if ((dma_audio_start < RAM_D2_DMA_MPU_BASE) ||
      (dma_audio_end > (RAM_D2_DMA_MPU_BASE + RAM_D2_DMA_MPU_COVERED_BYTES)))
  {
    Error_Handler();
  }

  const uintptr_t dma_cacheable_start = (uintptr_t)&__ram_d2_dma_cacheable_start__;
  const uintptr_t dma_cacheable_end = (uintptr_t)&__ram_d2_dma_cacheable_end__;
  if ((dma_cacheable_start < RAM_D2_DMA_CACHEABLE_BASE) ||
      (dma_cacheable_end > RAM_D2_DMA_CACHEABLE_END))
  {
    Error_Handler();
  }

  const uintptr_t stack_guard_start = (uintptr_t)&__stack_guard_start__;
  const uintptr_t stack_limit = (uintptr_t)&__stack_limit__;
  const uintptr_t stack_end = (uintptr_t)&_estack;
  if (((stack_guard_start & (MSP_GUARD_BYTES - 1U)) != 0U)
      || (stack_limit - stack_guard_start != MSP_GUARD_BYTES)
      || (stack_end - stack_limit != MSP_PROVISIONAL_STACK_BYTES))
  {
    Error_Handler();
  }

  MPU_Config();
  msp_stack_monitor_init();
  /* USER CODE END 1 */

  /* Enable the CPU Cache */

  /* Enable I-Cache---------------------------------------------------------*/
  SCB_EnableICache();

  /* Enable D-Cache---------------------------------------------------------*/
  SCB_EnableDCache();

  /* MCU Configuration--------------------------------------------------------*/

  /* Reset of all peripherals, Initializes the Flash interface and the Systick. */
  HAL_Init();

  /* Configure the system clock */
  SystemClock_Config();

  /* Configure the peripherals common clocks */
  PeriphCommonClock_Config();

  /* Initialize all configured peripherals */
  MX_GPIO_Init();
  MX_DMA_Init();
  MX_UART4_Init();
  MX_FMC_Init();
  MX_SPI5_Init();
  MX_I2C1_Init();
  MX_ADC2_Init();
  MX_SAI1_Init();
  MX_ADC1_Init();
  MX_TIM2_Init();
  MX_TIM6_Init();
  MX_TIM7_Init();
  MX_TIM5_Init();
  MX_TIM12_Init();
  MX_SDMMC1_SD_Init();
  /* USER CODE BEGIN 2 */
  board_power_hold_enable_after_boot_press();
  __HAL_TIM_SET_COUNTER(&htim5, 0U);
  HAL_TIM_Base_Start(&htim5);
  HAL_TIM_OC_Start(&htim5, TIM_CHANNEL_1);
  HAL_TIM_Base_Start_IT(&htim12);
  MX_FATFS_Init();
  brick6_app_init();
  led_init();
  uint32_t last_tick = 0;
  uint32_t ui_tasklet_divider = 0U;

  /* USER CODE END 2 */

  /* Infinite loop */
  while (1)
  {

    /* USER CODE BEGIN 3 */

         if (power_shutdown_service(HAL_GetTick()) != 0U)
         {
             continue;
         }

	     board_usb_process();
	     brick6_app_process();
	     board_usb_process();
	     lowcost_bootloader_shift_step16_service();
	     msp_stack_monitor_service();

	     uint32_t ui_ticks_processed = 0U;
	     while ((engine_tick_count != last_tick) && (ui_ticks_processed < UI_TASKLET_CATCHUP_BUDGET))
	     {
	         last_tick++;
	         ui_tasklet_divider++;
	         if (ui_tasklet_divider < UI_TASKLET_ENGINE_DIVIDER)
	         {
	             continue;
	         }

	         ui_tasklet_divider = 0U;
	         ui_tasklet_poll();
	         ui_ticks_processed++;
	     }

	     if (ui_tasklet_is_initialized() != 0U)
	     {
	         ui_renderer_oled_service_poll();
	         display_flush_service_poll();
	     }

  }
  /* USER CODE END 3 */
}

void SystemClock_Config(void)
{
  RCC_OscInitTypeDef RCC_OscInitStruct = {0};
  RCC_ClkInitTypeDef RCC_ClkInitStruct = {0};

  /** Supply configuration update enable
  */
  HAL_PWREx_ConfigSupply(PWR_LDO_SUPPLY);

  /** Configure the main internal regulator output voltage
  */
  __HAL_PWR_VOLTAGESCALING_CONFIG(PWR_REGULATOR_VOLTAGE_SCALE0);

  while(!__HAL_PWR_GET_FLAG(PWR_FLAG_VOSRDY)) {}

  /** Initializes the RCC Oscillators according to the specified parameters
  * in the RCC_OscInitTypeDef structure.
  */
  RCC_OscInitStruct.OscillatorType = RCC_OSCILLATORTYPE_HSI48|RCC_OSCILLATORTYPE_HSE;
  RCC_OscInitStruct.HSEState = RCC_HSE_ON;
  RCC_OscInitStruct.HSI48State = RCC_HSI48_ON;
  RCC_OscInitStruct.PLL.PLLState = RCC_PLL_ON;
  RCC_OscInitStruct.PLL.PLLSource = RCC_PLLSOURCE_HSE;
  RCC_OscInitStruct.PLL.PLLM = 3;
  RCC_OscInitStruct.PLL.PLLN = 240;
  RCC_OscInitStruct.PLL.PLLP = 2;
  RCC_OscInitStruct.PLL.PLLQ = 20;
  RCC_OscInitStruct.PLL.PLLR = 2;
  RCC_OscInitStruct.PLL.PLLRGE = RCC_PLL1VCIRANGE_2;
  RCC_OscInitStruct.PLL.PLLVCOSEL = RCC_PLL1VCOWIDE;
  RCC_OscInitStruct.PLL.PLLFRACN = 0;
  if (HAL_RCC_OscConfig(&RCC_OscInitStruct) != HAL_OK)
  {
    Error_Handler();
  }

  /** Initializes the CPU, AHB and APB buses clocks
  */
  RCC_ClkInitStruct.ClockType = RCC_CLOCKTYPE_HCLK|RCC_CLOCKTYPE_SYSCLK
                              |RCC_CLOCKTYPE_PCLK1|RCC_CLOCKTYPE_PCLK2
                              |RCC_CLOCKTYPE_D3PCLK1|RCC_CLOCKTYPE_D1PCLK1;
  RCC_ClkInitStruct.SYSCLKSource = RCC_SYSCLKSOURCE_PLLCLK;
  RCC_ClkInitStruct.SYSCLKDivider = RCC_SYSCLK_DIV1;
  RCC_ClkInitStruct.AHBCLKDivider = RCC_HCLK_DIV2;
  RCC_ClkInitStruct.APB3CLKDivider = RCC_APB3_DIV2;
  RCC_ClkInitStruct.APB1CLKDivider = RCC_APB1_DIV2;
  RCC_ClkInitStruct.APB2CLKDivider = RCC_APB2_DIV2;
  RCC_ClkInitStruct.APB4CLKDivider = RCC_APB4_DIV2;

  if (HAL_RCC_ClockConfig(&RCC_ClkInitStruct, FLASH_LATENCY_4) != HAL_OK)
  {
    Error_Handler();
  }
}

void PeriphCommonClock_Config(void)
{
  RCC_PeriphCLKInitTypeDef PeriphClkInitStruct = {0};

  /** Initializes the peripherals clock
  */
  PeriphClkInitStruct.PeriphClockSelection = RCC_PERIPHCLK_FMC|RCC_PERIPHCLK_ADC
                              |RCC_PERIPHCLK_SDMMC|RCC_PERIPHCLK_SAI1;
  PeriphClkInitStruct.PLL2.PLL2M = 3;
  PeriphClkInitStruct.PLL2.PLL2N = 150;
  PeriphClkInitStruct.PLL2.PLL2P = 20;
  PeriphClkInitStruct.PLL2.PLL2Q = 1;
  PeriphClkInitStruct.PLL2.PLL2R = 3;
  PeriphClkInitStruct.PLL2.PLL2RGE = RCC_PLL2VCIRANGE_2;
  PeriphClkInitStruct.PLL2.PLL2VCOSEL = RCC_PLL2VCOWIDE;
  PeriphClkInitStruct.PLL2.PLL2FRACN = 0;
  PeriphClkInitStruct.PLL3.PLL3M = 5;
  PeriphClkInitStruct.PLL3.PLL3N = 256;
  PeriphClkInitStruct.PLL3.PLL3P = 25;
  PeriphClkInitStruct.PLL3.PLL3Q = 2;
  PeriphClkInitStruct.PLL3.PLL3R = 2;
  PeriphClkInitStruct.PLL3.PLL3RGE = RCC_PLL3VCIRANGE_1;
  PeriphClkInitStruct.PLL3.PLL3VCOSEL = RCC_PLL3VCOWIDE;
  PeriphClkInitStruct.PLL3.PLL3FRACN = 0;
  PeriphClkInitStruct.FmcClockSelection = RCC_FMCCLKSOURCE_D1HCLK;
  PeriphClkInitStruct.SdmmcClockSelection = RCC_SDMMCCLKSOURCE_PLL2;
  PeriphClkInitStruct.Sai1ClockSelection = RCC_SAI1CLKSOURCE_PLL3;
  PeriphClkInitStruct.AdcClockSelection = RCC_ADCCLKSOURCE_PLL2;
  if (HAL_RCCEx_PeriphCLKConfig(&PeriphClkInitStruct) != HAL_OK)
  {
    Error_Handler();
  }
}

void Error_Handler(void)
{
  __disable_irq();
  while (1)
  {
  }
}
#ifdef USE_FULL_ASSERT
/**
  * @brief  Reports the name of the source file and the source line number
  *         where the assert_param error has occurred.
  * @param  file: pointer to the source file name
  * @param  line: assert_param error line source number
  * @retval None
  */
void assert_failed(uint8_t *file, uint32_t line)
{
  /* USER CODE BEGIN 6 */
  /* User can add his own implementation to report the file name and line number,
     ex: log backend optionnel si nécessaire */
  /* USER CODE END 6 */
}
#endif /* USE_FULL_ASSERT */
